# CY8C5888LTI_LP097 register map
File version: 0.1
CY8C58LP
Registers are 8-bit, read-write, no defined reset value unless marked. A register's access mark holds for its fields unless they carry their own. Offsets are from the block's base; lines under a group give offsets from that group; [hi:lo] are bit positions; {n}, {i} and the like mark numbered series; 'fields as' and 'values as' point back to an identical list; <NAME> marks a mode.

## Memory map
0x00000000 StepperStart
0x00000000 MotorKill
0x00000000 StepperStep
0x00000000 StepCountReset
0x00000000 StepperDirection
0x00000000 StepperCount
0x00000000 LEDDrive
0x00000000 ByteCounter
0x00000000 LabVIEW_UART — UART
0x00000000 UARTReset
0x00000000 Direction
0x00000000 ByteCountReset
0x00000000 MotorDrive

## StepperStart
Base 0x00000000
0x4000647C StepperStart_CONTROL_REG

## MotorKill
Base 0x00000000
0x40006476 MotorKill_CONTROL_REG

## StepperStep
Base 0x00000000
0x40006408 StepperStep_COUNTER 32-bit — UDB.A0 - Current Down Counter Value
0x40006428 StepperStep_PERIOD 32-bit — UDB.D0 - Assigned Period
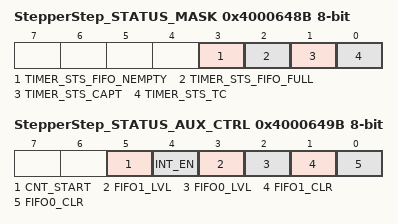
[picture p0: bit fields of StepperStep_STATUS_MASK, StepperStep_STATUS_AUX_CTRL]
0x4000648B StepperStep_STATUS_MASK — UDB Status bits Interrupt Mask Enable Register
  [3] TIMER_STS_FIFO_NEMPTY ro — FIFO Empty status
  [2] TIMER_STS_FIFO_FULL ro — FIFO Full Status
  [1] TIMER_STS_CAPT ro — Enables the Interrupt on Capture
  [0] TIMER_STS_TC ro — Enables the Interrupt on TC
0x4000649B StepperStep_STATUS_AUX_CTRL — UDB Auxilliary Control Register
  [5] CNT_START — FIFO0 clear
    0=E_CNT_START0 (Disable counter); 1=E_CNT_START1 (Enable counter)
  [4] INT_EN
    0=E_INT_EN0 (Interrupt disabled); 1=E_INT_EN1 (Interrupt enabled)
  [3] FIFO1_LVL — FIFO level
    0=E_FIFO_LVL_0 (FIFO LVL: input mode: FIFO not full; output mode: FIFO not empty); 1=E_FIFO_LVL_1 (FIFO LVL: input mode: FIFO at least 1/2 empty; output mode: FIFO at least 1/2 full)
  [2] FIFO0_LVL — FIFO level
    values as FIFO1_LVL
  [1] FIFO1_CLR — FIFO1 clear
    0=E_FIFO_CLR_0 (Normal FIFO operation); 1=E_FIFO_CLR_1 (Clear FIFO state)
  [0] FIFO0_CLR — FIFO0 clear
    values as FIFO1_CLR

## StepCountReset
Base 0x00000000
0x4000647F StepCountReset_CONTROL_REG

## StepperDirection
Base 0x00000000
0x4000647D StepperDirection_CONTROL_REG

## StepperCount
Base 0x00000000
0x4000640C StepperCount_COUNTER 32-bit — UDB.A0 - Current Counter Value
0x4000642C StepperCount_PERIOD 32-bit — UDB.D0 - Assigned Period
0x4000643C StepperCount_COMPARE 32-bit — UDB.D1 - Assigned Compare Value
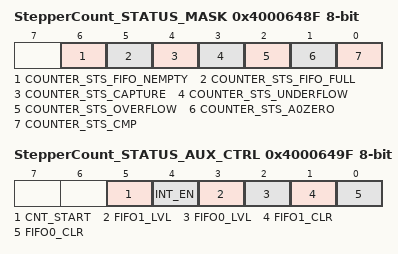
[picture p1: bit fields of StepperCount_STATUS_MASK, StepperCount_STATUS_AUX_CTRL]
0x4000648F StepperCount_STATUS_MASK — UDB Status bits Interrupt Mask Enable Register
  [6] COUNTER_STS_FIFO_NEMPTY — FIFO Not Empty Status
  [5] COUNTER_STS_FIFO_FULL — FIFO Full Status
  [4] COUNTER_STS_CAPTURE — Capture Status
  [3] COUNTER_STS_UNDERFLOW — Underflow status
  [2] COUNTER_STS_OVERFLOW — Overflow status
  [1] COUNTER_STS_A0ZERO — A0 Zero ouput status
  [0] COUNTER_STS_CMP — Compare output status
0x4000649F StepperCount_STATUS_AUX_CTRL — UDB Auxilliary Control Register
  fields as StepperStep.StepperStep_STATUS_AUX_CTRL

## LEDDrive
Base 0x00000000
0x4000647A LEDDrive_CONTROL_REG

## ByteCounter
Base 0x00000000
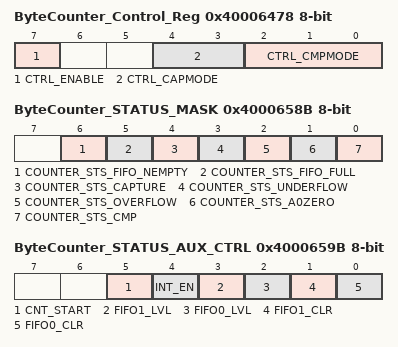
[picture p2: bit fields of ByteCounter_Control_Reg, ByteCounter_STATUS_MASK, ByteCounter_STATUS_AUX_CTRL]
0x40006478 ByteCounter_Control_Reg — UDB Control Register - Assigned Control Register Value
  [7] CTRL_ENABLE — Enable Counter
  [4:3] CTRL_CAPMODE — Capture mode
  [2:0] CTRL_CMPMODE — Compare mode
0x40006508 ByteCounter_COUNTER — UDB.A0 - Current Counter Value
0x40006528 ByteCounter_PERIOD — UDB.D0 - Assigned Period
0x40006538 ByteCounter_COMPARE — UDB.D1 - Assigned Compare Value
0x4000658B ByteCounter_STATUS_MASK — UDB Status bits Interrupt Mask Enable Register
  fields as StepperCount.StepperCount_STATUS_MASK
0x4000659B ByteCounter_STATUS_AUX_CTRL — UDB Auxilliary Control Register
  fields as StepperStep.StepperStep_STATUS_AUX_CTRL

## LabVIEW_UART — UART
Base 0x00000000
0x40006447 TX_LabVIEW_UART_TX_DATA — TX Data Register
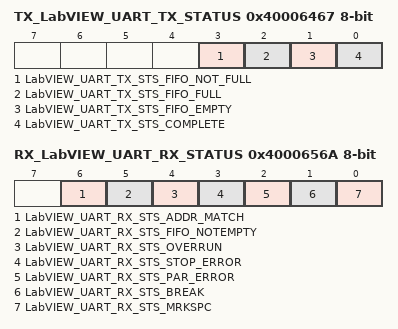
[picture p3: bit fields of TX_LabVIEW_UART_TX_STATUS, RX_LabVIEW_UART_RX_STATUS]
0x40006467 TX_LabVIEW_UART_TX_STATUS — TX status register
  [3] LabVIEW_UART_TX_STS_FIFO_NOT_FULL ro, [2] LabVIEW_UART_TX_STS_FIFO_FULL ro, [1] LabVIEW_UART_TX_STS_FIFO_EMPTY ro, [0] LabVIEW_UART_TX_STS_COMPLETE ro
0x4000652A RX_LabVIEW_UART_RX_ADDRESS1 — RX Address1 Register
0x4000653A RX_LabVIEW_UART_RX_ADDRESS2 — RX Address2 Register
0x4000654A RX_LabVIEW_UART_RX_DATA — RX Data Register
0x4000656A RX_LabVIEW_UART_RX_STATUS — RX status register
  [6] LabVIEW_UART_RX_STS_ADDR_MATCH ro, [5] LabVIEW_UART_RX_STS_FIFO_NOTEMPTY ro, [4] LabVIEW_UART_RX_STS_OVERRUN ro, [3] LabVIEW_UART_RX_STS_STOP_ERROR ro, [2] LabVIEW_UART_RX_STS_PAR_ERROR ro, [1] LabVIEW_UART_RX_STS_BREAK ro, [0] LabVIEW_UART_RX_STS_MRKSPC ro

## UARTReset
Base 0x00000000
0x4000657B UARTReset_CONTROL_REG

## Direction
Base 0x00000000
0x40006574 Direction_CONTROL_REG

## ByteCountReset
Base 0x00000000
0x40006578 ByteCountReset_CONTROL_REG

## MotorDrive
Base 0x00000000
0x40006525 MotorDrive_COMPARE_Reg 16-bit — UDB.D0 - Assigned Compare Value
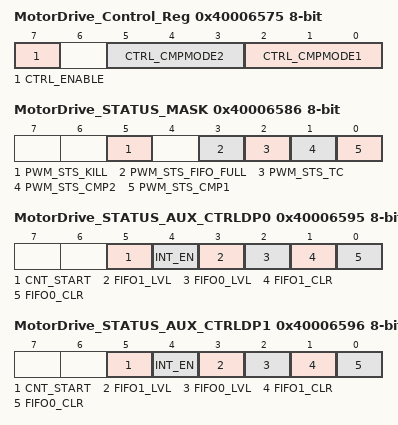
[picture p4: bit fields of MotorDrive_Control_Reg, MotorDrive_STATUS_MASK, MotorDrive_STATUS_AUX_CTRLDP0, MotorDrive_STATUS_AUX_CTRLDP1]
0x40006575 MotorDrive_Control_Reg — UDB Control Register - Assigned Control Register Value
  [7] CTRL_ENABLE — Enable the PWM
  [5:3] CTRL_CMPMODE2 — Compare mode 2
  [2:0] CTRL_CMPMODE1 — Compare mode 1
0x40006586 MotorDrive_STATUS_MASK — UDB Status bits Interrupt Mask Enable Register
  [5] PWM_STS_KILL ro — Enables the Interrupt on Kill
  [3] PWM_STS_FIFO_FULL ro — FIFO Full Status Mask
  [2] PWM_STS_TC ro — Enables the Interrupt on Terminal Count
  [1] PWM_STS_CMP2 ro — Enables the Interrupt on Compare 2
  [0] PWM_STS_CMP1 ro — Enables the Interrupt on Compare 1
0x40006595 MotorDrive_STATUS_AUX_CTRLDP0 — UDB Auxilliary Control Register
  fields as StepperStep.StepperStep_STATUS_AUX_CTRL
0x40006596 MotorDrive_STATUS_AUX_CTRLDP1 — UDB Auxilliary Control Register
  fields as StepperStep.StepperStep_STATUS_AUX_CTRL
